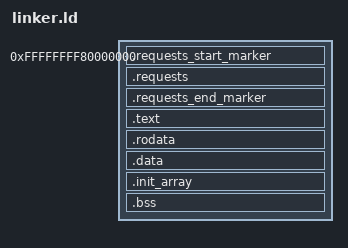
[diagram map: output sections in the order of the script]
OUTPUT_FORMAT(elf64-x86-64)
OUTPUT_ARCH(i386:x86-64)
ENTRY(kmain)

PHDRS
{
    requests PT_LOAD FLAGS(4);
    text     PT_LOAD FLAGS(5);
    rodata   PT_LOAD FLAGS(4);
    data     PT_LOAD FLAGS(6);
}

SECTIONS
{
    . = 0xffffffff80000000;

    .requests_start_marker : {
        KEEP(*(.requests_start_marker))
    } :requests

    .requests : {
        KEEP(*(.requests))
    } :requests

    .requests_end_marker : {
        KEEP(*(.requests_end_marker))
    } :requests

    . = ALIGN(CONSTANT(MAXPAGESIZE));

    .text : {
        *(.text .text.*)
    } :text

    . = ALIGN(CONSTANT(MAXPAGESIZE));

    .rodata : {
        *(.rodata .rodata.*)
    } :rodata

    . = ALIGN(CONSTANT(MAXPAGESIZE));

    .data : {
        *(.data .data.*)
    } :data

    .init_array : {
        __init_array_start = .;
        KEEP(*(.init_array*))
        __init_array_end = .;
    } :data

    .bss : {
        *(.bss .bss.*)
        *(COMMON)
    } :data

    /DISCARD/ : {
        *(.eh_frame*)
        *(.note*)
        *(.comment*)
    }
}
